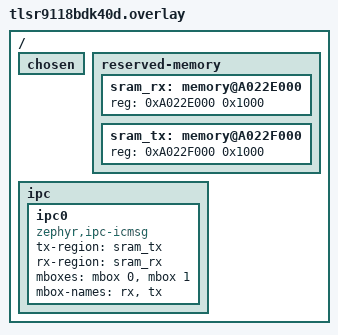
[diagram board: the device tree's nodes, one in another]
/*
 * SPDX-License-Identifier: Apache-2.0
 *
 * Copyright (c) 2023 Telink Semiconductor (Shanghai) Co., Ltd.
 */

/ {
	chosen {
		/delete-property/ zephyr,ipc_shm;
	};

	reserved-memory {
		/delete-node/ memory@0022E000;
		/delete-node/ memory@0022F000;

		sram_rx: memory@A022E000 {
			reg = <0xA022E000 0x1000>;
		};

		sram_tx: memory@A022F000 {
			reg = <0xA022F000 0x1000>;
		};
	};

	ipc {
		/delete-node/ ipc0;

		ipc0: ipc0 {
			compatible = "zephyr,ipc-icmsg";
			tx-region = <&sram_tx>;
			rx-region = <&sram_rx>;
			mboxes = <&mbox 0>, <&mbox 1>;
			mbox-names = "rx", "tx";
			status = "okay";
		};
	};
};
